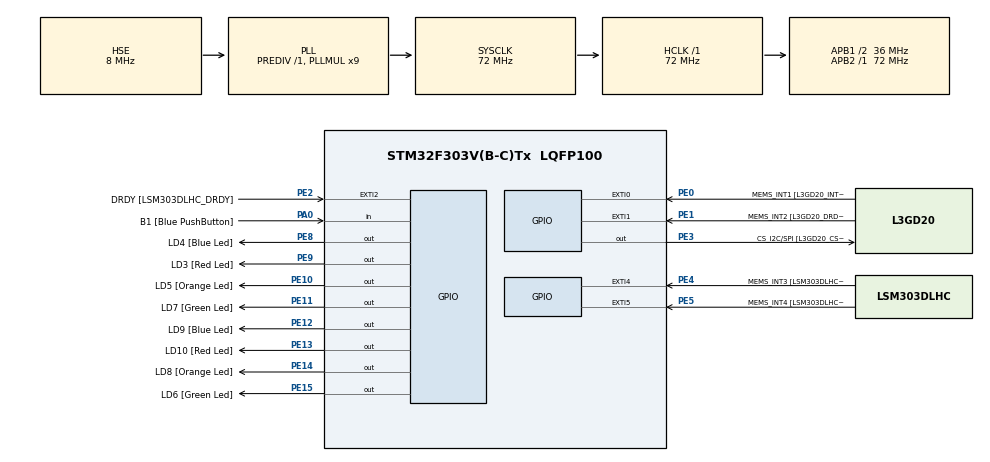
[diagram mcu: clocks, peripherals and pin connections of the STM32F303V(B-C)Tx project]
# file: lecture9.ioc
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FREERTOS.Tasks01=defaultTask,0,128,StartDefaultTask,Default,NULL,Dynamic,NULL,NULL;GreenLedTask,0,128,StartGreenLedTask,Default,NULL,Dynamic,NULL,NULL;RedLedTask,0,128,StartRedLedTask,Default,NULL,Dynamic,NULL,NULL;KeyScan,0,128,StartKeyScan,Default,NULL,Dynamic,NULL,NULL
Mcu.Family=STM32F3
Mcu.Name=STM32F303V(B-C)Tx
Mcu.Package=LQFP100
NVIC.PriorityGroup=NVIC_PRIORITYGROUP_4
NVIC.TIM2_IRQn=true\:0\:0\:false\:false\:true\:false\:false\:true
NVIC.TimeBase=TIM2_IRQn
NVIC.TimeBaseIP=TIM2
PA0.GPIO_Label=B1 [Blue PushButton]
PA0.GPIO_Mode=GPIO_MODE_INPUT
PA0.GPIO_PuPd=GPIO_NOPULL
PA0.Signal=GPIO_Input
PA11.GPIO_Label=DM
PA11.Signal=USB_DM
PA12.GPIO_Label=DP
PA12.Signal=USB_DP
PA13.GPIO_Label=SWDIO
PA13.Signal=SYS_JTMS-SWDIO
PA14.GPIO_Label=SWCLK
PA14.Signal=SYS_JTCK-SWCLK
PA5.GPIO_Label=SPI1_SCK [L3GD20_SCL/SPC]
PA5.GPIO_Mode=GPIO_MODE_AF_PP
PA5.GPIO_PuPd=GPIO_NOPULL
PA5.GPIO_Speed=GPIO_SPEED_FREQ_LOW
PA5.Signal=SPI1_SCK
PA6.GPIO_Label=SPI1_MISO [L3GD20_SA0/SDO]
PA6.GPIO_Mode=GPIO_MODE_AF_PP
PA6.GPIO_PuPd=GPIO_NOPULL
PA6.GPIO_Speed=GPIO_SPEED_FREQ_LOW
PA6.Signal=SPI1_MISO
PA7.GPIO_Label=SPI1_MISO [L3GD20_SDA/SDI/SDO]
PA7.GPIO_Mode=GPIO_MODE_AF_PP
PA7.GPIO_PuPd=GPIO_NOPULL
PA7.GPIO_Speed=GPIO_SPEED_FREQ_LOW
PA7.Signal=SPI1_MOSI
PB3.GPIO_Label=SWO
PB3.Signal=SYS_JTDO-TRACESWO
PB6.GPIO_FM6=__NULL
PB6.GPIO_Label=I2C1_SCL [LSM303DLHC_SCL]
PB6.GPIO_Mode=GPIO_MODE_AF_OD
PB6.GPIO_PuPd=GPIO_NOPULL
PB6.GPIO_Speed=GPIO_SPEED_FREQ_LOW
PB6.Signal=I2C1_SCL
PB7.GPIO_FM7=__NULL
PB7.GPIO_Label=I2C1_SDA [LSM303DLHC_SDA]
PB7.GPIO_Mode=GPIO_MODE_AF_OD
PB7.GPIO_PuPd=GPIO_NOPULL
PB7.GPIO_Speed=GPIO_SPEED_FREQ_LOW
PB7.Signal=I2C1_SDA
PC14-OSC32_IN.GPIO_Label=OSC32_IN
PC14-OSC32_IN.Signal=RCC_OSC32_IN
PC15-OSC32_OUT.GPIO_Label=OSC32_OUT
PC15-OSC32_OUT.Signal=RCC_OSC32_OUT
PE0.GPIO_Label=MEMS_INT1 [L3GD20_INT1]
PE0.GPIO_ModeDefaultEXTI=GPIO_MODE_EVT_RISING
PE0.GPIO_PuPd=GPIO_NOPULL
PE0.Signal=GPXTI0
PE1.GPIO_Label=MEMS_INT2 [L3GD20_DRDY/INT2]
PE1.GPIO_ModeDefaultEXTI=GPIO_MODE_EVT_RISING
PE1.GPIO_PuPd=GPIO_NOPULL
PE1.Signal=GPXTI1
PE10.GPIO_Label=LD5 [Orange Led]
PE10.GPIO_ModeDefaultOutputPP=GPIO_MODE_OUTPUT_PP
PE10.GPIO_PuPd=GPIO_NOPULL
PE10.GPIO_Speed=GPIO_SPEED_FREQ_LOW
PE10.Signal=GPIO_Output
PE11.GPIO_Label=LD7 [Green Led]
PE11.GPIO_ModeDefaultOutputPP=GPIO_MODE_OUTPUT_PP
PE11.GPIO_PuPd=GPIO_NOPULL
PE11.GPIO_Speed=GPIO_SPEED_FREQ_LOW
PE11.Signal=GPIO_Output
PE12.GPIO_Label=LD9 [Blue Led]
PE12.GPIO_ModeDefaultOutputPP=GPIO_MODE_OUTPUT_PP
PE12.GPIO_PuPd=GPIO_NOPULL
PE12.GPIO_Speed=GPIO_SPEED_FREQ_LOW
PE12.Signal=GPIO_Output
PE13.GPIO_Label=LD10 [Red Led]
PE13.GPIO_ModeDefaultOutputPP=GPIO_MODE_OUTPUT_PP
PE13.GPIO_PuPd=GPIO_NOPULL
PE13.GPIO_Speed=GPIO_SPEED_FREQ_LOW
PE13.Signal=GPIO_Output
PE14.GPIO_Label=LD8 [Orange Led]
PE14.GPIO_ModeDefaultOutputPP=GPIO_MODE_OUTPUT_PP
PE14.GPIO_PuPd=GPIO_NOPULL
PE14.GPIO_Speed=GPIO_SPEED_FREQ_LOW
PE14.Signal=GPIO_Output
PE15.GPIO_Label=LD6 [Green Led]
PE15.GPIO_ModeDefaultOutputPP=GPIO_MODE_OUTPUT_PP
PE15.GPIO_PuPd=GPIO_NOPULL
PE15.GPIO_Speed=GPIO_SPEED_FREQ_LOW
PE15.Signal=GPIO_Output
PE2.GPIO_Label=DRDY [LSM303DLHC_DRDY]
PE2.GPIO_ModeDefaultEXTI=GPIO_MODE_EVT_RISING
PE2.GPIO_PuPd=GPIO_NOPULL
PE2.Signal=GPXTI2
PE3.GPIO_Label=CS_I2C/SPI [L3GD20_CS_I2C/SPI]
PE3.GPIO_ModeDefaultOutputPP=GPIO_MODE_OUTPUT_PP
PE3.GPIO_PuPd=GPIO_NOPULL
PE3.GPIO_Speed=GPIO_SPEED_FREQ_LOW
PE3.Signal=GPIO_Output
PE4.GPIO_Label=MEMS_INT3 [LSM303DLHC_INT1]
PE4.GPIO_ModeDefaultEXTI=GPIO_MODE_EVT_RISING
PE4.GPIO_PuPd=GPIO_NOPULL
PE4.Signal=GPXTI4
PE5.GPIO_Label=MEMS_INT4 [LSM303DLHC_INT2]
PE5.GPIO_ModeDefaultEXTI=GPIO_MODE_EVT_RISING
PE5.GPIO_PuPd=GPIO_NOPULL
PE5.Signal=GPXTI5
PE8.GPIO_Label=LD4 [Blue Led]
PE8.GPIO_ModeDefaultOutputPP=GPIO_MODE_OUTPUT_PP
PE8.GPIO_PuPd=GPIO_NOPULL
PE8.GPIO_Speed=GPIO_SPEED_FREQ_LOW
PE8.Signal=GPIO_Output
PE9.GPIO_Label=LD3 [Red Led]
PE9.GPIO_ModeDefaultOutputPP=GPIO_MODE_OUTPUT_PP
PE9.GPIO_PuPd=GPIO_NOPULL
PE9.GPIO_Speed=GPIO_SPEED_FREQ_LOW
PE9.Signal=GPIO_Output
PF0-OSC_IN.GPIO_Label=OSC_IN
PF0-OSC_IN.Mode=HSE-External-Oscillator
PF0-OSC_IN.Signal=RCC_OSC_IN
PF1-OSC_OUT.GPIO_Label=OSC_OUT
PF1-OSC_OUT.Mode=HSE-External-Oscillator
PF1-OSC_OUT.Signal=RCC_OSC_OUT
ProjectManager.HeapSize=0x200
ProjectManager.StackSize=0x400
ProjectManager.TargetToolchain=MDK-ARM V5.27
RCC.AHBFreq_Value=72000000
RCC.APB1CLKDivider=RCC_HCLK_DIV2
RCC.APB1Freq_Value=36000000
RCC.APB1TimFreq_Value=72000000
RCC.APB2Freq_Value=72000000
RCC.APB2TimFreq_Value=72000000
RCC.CortexFreq_Value=72000000
RCC.HCLKFreq_Value=72000000
RCC.HSE_VALUE=8000000
RCC.HSI_VALUE=8000000
RCC.LSE_VALUE=32768
RCC.PLLMUL=RCC_PLL_MUL9
RCC.PLLSourceVirtual=RCC_PLLSOURCE_HSE
RCC.SYSCLKFreq_VALUE=72000000
RCC.SYSCLKSourceVirtual=RCC_SYSCLKSOURCE_PLLCLK
RCC.USBFreq_Value=72000000
VP_FREERTOS_VS_CMSIS_V1.Mode=CMSIS_V1
VP_SYS_VS_tim2.Mode=TIM2
board=STM32F3DISCOVERY

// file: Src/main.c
/* USER CODE BEGIN Header */
/**
  ******************************************************************************
  * @file           : main.c
  * @brief          : Main program body
  ******************************************************************************
  * @attention
  *
  * <h2><center>&copy; Copyright (c) 2020 STMicroelectronics.
  * All rights reserved.</center></h2>
  *
  * This software component is licensed by ST under Ultimate Liberty license
  * SLA0044, the "License"; You may not use this file except in compliance with
  * the License. You may obtain a copy of the License at:
  *                             www.st.com/SLA0044
  *
  ******************************************************************************
  */
/* USER CODE END Header */

#include "main.h"
#include "cmsis_os.h"

osThreadId defaultTaskHandle;
osThreadId GreenLedTaskHandle;
osThreadId RedLedTaskHandle;
osThreadId KeyScanHandle;

void SystemClock_Config(void);
static void MX_GPIO_Init(void);
void StartDefaultTask(void const * argument);
void StartGreenLedTask(void const * argument);
void StartRedLedTask(void const * argument);
void StartKeyScan(void const * argument);

int main(void)
{

  /* MCU Configuration--------------------------------------------------------*/

  /* Reset of all peripherals, Initializes the Flash interface and the Systick. */
  HAL_Init();

  /* Configure the system clock */
  SystemClock_Config();

  /* Initialize all configured peripherals */
  MX_GPIO_Init();

  /* Create the thread(s) */
  /* definition and creation of defaultTask */
  osThreadDef(defaultTask, StartDefaultTask, osPriorityNormal, 0, 128);
  defaultTaskHandle = osThreadCreate(osThread(defaultTask), NULL);

  /* definition and creation of GreenLedTask */
  osThreadDef(GreenLedTask, StartGreenLedTask, osPriorityNormal, 0, 128);
  GreenLedTaskHandle = osThreadCreate(osThread(GreenLedTask), NULL);

  /* definition and creation of RedLedTask */
  osThreadDef(RedLedTask, StartRedLedTask, osPriorityNormal, 0, 128);
  RedLedTaskHandle = osThreadCreate(osThread(RedLedTask), NULL);

  /* definition and creation of KeyScan */
  osThreadDef(KeyScan, StartKeyScan, osPriorityNormal, 0, 128);
  KeyScanHandle = osThreadCreate(osThread(KeyScan), NULL);

  /* Start scheduler */
  osKernelStart();

  /* We should never get here as control is now taken by the scheduler */

  /* Infinite loop */
  while (1)
  {

  }
}

void SystemClock_Config(void)
{
  RCC_OscInitTypeDef RCC_OscInitStruct = {0};
  RCC_ClkInitTypeDef RCC_ClkInitStruct = {0};

  /** Initializes the CPU, AHB and APB busses clocks
  */
  RCC_OscInitStruct.OscillatorType = RCC_OSCILLATORTYPE_HSE;
  RCC_OscInitStruct.HSEState = RCC_HSE_ON;
  RCC_OscInitStruct.HSEPredivValue = RCC_HSE_PREDIV_DIV1;
  RCC_OscInitStruct.HSIState = RCC_HSI_ON;
  RCC_OscInitStruct.PLL.PLLState = RCC_PLL_ON;
  RCC_OscInitStruct.PLL.PLLSource = RCC_PLLSOURCE_HSE;
  RCC_OscInitStruct.PLL.PLLMUL = RCC_PLL_MUL9;
  if (HAL_RCC_OscConfig(&RCC_OscInitStruct) != HAL_OK)
  {
    Error_Handler();
  }
  /** Initializes the CPU, AHB and APB busses clocks
  */
  RCC_ClkInitStruct.ClockType = RCC_CLOCKTYPE_HCLK|RCC_CLOCKTYPE_SYSCLK
                              |RCC_CLOCKTYPE_PCLK1|RCC_CLOCKTYPE_PCLK2;
  RCC_ClkInitStruct.SYSCLKSource = RCC_SYSCLKSOURCE_PLLCLK;
  RCC_ClkInitStruct.AHBCLKDivider = RCC_SYSCLK_DIV1;
  RCC_ClkInitStruct.APB1CLKDivider = RCC_HCLK_DIV2;
  RCC_ClkInitStruct.APB2CLKDivider = RCC_HCLK_DIV1;

  if (HAL_RCC_ClockConfig(&RCC_ClkInitStruct, FLASH_LATENCY_2) != HAL_OK)
  {
    Error_Handler();
  }
}

static void MX_GPIO_Init(void)
{
  GPIO_InitTypeDef GPIO_InitStruct = {0};

  /* GPIO Ports Clock Enable */
  __HAL_RCC_GPIOE_CLK_ENABLE();
  __HAL_RCC_GPIOC_CLK_ENABLE();
  __HAL_RCC_GPIOF_CLK_ENABLE();
  __HAL_RCC_GPIOA_CLK_ENABLE();
  __HAL_RCC_GPIOB_CLK_ENABLE();

  /*Configure GPIO pin Output Level */
  HAL_GPIO_WritePin(GPIOE, CS_I2C_SPI_Pin|LD4_Pin|LD3_Pin|LD5_Pin
                          |LD7_Pin|LD9_Pin|LD10_Pin|LD8_Pin
                          |LD6_Pin, GPIO_PIN_RESET);

  /*Configure GPIO pins : DRDY_Pin MEMS_INT3_Pin MEMS_INT4_Pin MEMS_INT1_Pin
                           MEMS_INT2_Pin */
  GPIO_InitStruct.Pin = DRDY_Pin|MEMS_INT3_Pin|MEMS_INT4_Pin|MEMS_INT1_Pin
                          |MEMS_INT2_Pin;
  GPIO_InitStruct.Mode = GPIO_MODE_EVT_RISING;
  GPIO_InitStruct.Pull = GPIO_NOPULL;
  HAL_GPIO_Init(GPIOE, &GPIO_InitStruct);

  /*Configure GPIO pins : CS_I2C_SPI_Pin LD4_Pin LD3_Pin LD5_Pin
                           LD7_Pin LD9_Pin LD10_Pin LD8_Pin
                           LD6_Pin */
  GPIO_InitStruct.Pin = CS_I2C_SPI_Pin|LD4_Pin|LD3_Pin|LD5_Pin
                          |LD7_Pin|LD9_Pin|LD10_Pin|LD8_Pin
                          |LD6_Pin;
  GPIO_InitStruct.Mode = GPIO_MODE_OUTPUT_PP;
  GPIO_InitStruct.Pull = GPIO_NOPULL;
  GPIO_InitStruct.Speed = GPIO_SPEED_FREQ_LOW;
  HAL_GPIO_Init(GPIOE, &GPIO_InitStruct);

  /*Configure GPIO pin : B1_Pin */
  GPIO_InitStruct.Pin = B1_Pin;
  GPIO_InitStruct.Mode = GPIO_MODE_INPUT;
  GPIO_InitStruct.Pull = GPIO_NOPULL;
  HAL_GPIO_Init(B1_GPIO_Port, &GPIO_InitStruct);

  /*Configure GPIO pins : SPI1_SCK_Pin SPI1_MISO_Pin SPI1_MISOA7_Pin */
  GPIO_InitStruct.Pin = SPI1_SCK_Pin|SPI1_MISO_Pin|SPI1_MISOA7_Pin;
  GPIO_InitStruct.Mode = GPIO_MODE_AF_PP;
  GPIO_InitStruct.Pull = GPIO_NOPULL;
  GPIO_InitStruct.Speed = GPIO_SPEED_FREQ_LOW;
  GPIO_InitStruct.Alternate = GPIO_AF5_SPI1;
  HAL_GPIO_Init(GPIOA, &GPIO_InitStruct);

  /*Configure GPIO pins : DM_Pin DP_Pin */
  GPIO_InitStruct.Pin = DM_Pin|DP_Pin;
  GPIO_InitStruct.Mode = GPIO_MODE_AF_PP;
  GPIO_InitStruct.Pull = GPIO_NOPULL;
  GPIO_InitStruct.Speed = GPIO_SPEED_FREQ_HIGH;
  GPIO_InitStruct.Alternate = GPIO_AF14_USB;
  HAL_GPIO_Init(GPIOA, &GPIO_InitStruct);

  /*Configure GPIO pins : I2C1_SCL_Pin I2C1_SDA_Pin */
  GPIO_InitStruct.Pin = I2C1_SCL_Pin|I2C1_SDA_Pin;
  GPIO_InitStruct.Mode = GPIO_MODE_AF_OD;
  GPIO_InitStruct.Pull = GPIO_PULLUP;
  GPIO_InitStruct.Speed = GPIO_SPEED_FREQ_LOW;
  GPIO_InitStruct.Alternate = GPIO_AF4_I2C1;
  HAL_GPIO_Init(GPIOB, &GPIO_InitStruct);

}

void StartDefaultTask(void const * argument)
{
  for(;;)
  {
    osDelay(1);
  }
}

void StartGreenLedTask(void const * argument)
{
  /* USER CODE BEGIN StartGreenLedTask */
  /* Infinite loop */
  for(;;)
  {
      HAL_GPIO_TogglePin (GPIOE, GPIO_PIN_13);
      osDelay(500);
  }
  /* USER CODE END StartGreenLedTask */
}

void StartRedLedTask(void const * argument)
{
  /* USER CODE BEGIN StartRedLedTask */
  /* Infinite loop */
  for(;;)
  {
      HAL_GPIO_TogglePin (GPIOE, GPIO_PIN_9);
      osDelay(1000);
  }
  /* USER CODE END StartRedLedTask */
}

void StartKeyScan(void const * argument)
{
  /* USER CODE BEGIN StartKeyScan */
  /* Infinite loop */
  for(;;)
  {
      if (HAL_GPIO_ReadPin(B1_GPIO_Port, B1_Pin) == 1) {
        HAL_GPIO_WritePin(LD5_GPIO_Port, LD6_Pin, GPIO_PIN_SET);
      } else {
        HAL_GPIO_WritePin(LD5_GPIO_Port, LD6_Pin, GPIO_PIN_RESET);
      }
  }
  /* USER CODE END StartKeyScan */
}

void HAL_TIM_PeriodElapsedCallback(TIM_HandleTypeDef *htim)
{
  if (htim->Instance == TIM2) {
    HAL_IncTick();
  }
}

void Error_Handler(void)
{
}

/************************ (C) COPYRIGHT STMicroelectronics *****END OF FILE****/
